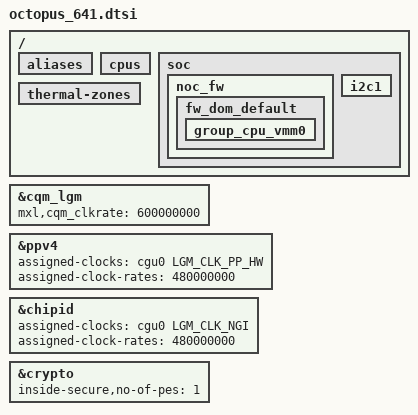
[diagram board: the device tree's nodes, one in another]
// SPDX-License-Identifier: GPL-2.0
/*
 * Copyright (C) 2022 MaxLinear, Inc.
 */

#include "octopus_851.dtsi"

/{
	aliases {
		/delete-property/ cpu2;
		/delete-property/ cpu3;
		/delete-property/ usb0;
		/delete-property/ pcie2;
		/delete-property/ pcie3;
		/delete-property/ pcie6;
		/delete-property/ pcie7;
		/delete-property/ cbphy1;
		/delete-property/ cbphy3;
	};

	cpus {
		/delete-node/ cpu@8;
		/delete-node/ cpu@a;
	};

	soc {
		/delete-node/ usb@0;
		/delete-node/ pcie@d1000000; /* PCIe30 */
		/delete-node/ pcie@d1100000; /* PCIe31 */
		/delete-node/ pcie@c1000000; /* PCIe40 */
		/delete-node/ pcie@c1100000; /* PCIe41 */
		/delete-node/ combophy1;
		/delete-node/ combophy3;

		noc_fw {
			fw_dom_default {
				group_cpu_vmm0 {
					/delete-node/ rule_cpu_vmm0_18;
					/delete-node/ rule_cpu_vmm0_19;
					/delete-node/ rule_cpu_vmm0_36;
					/delete-node/ rule_cpu_vmm0_37;
					/delete-node/ rule_cpu_vmm0_40;
					/delete-node/ rule_cpu_vmm0_41;
					/delete-node/ rule_cpu_vmm0_58;
					/delete-node/ rule_cpu_vmm0_59;
				};
			};
		};

		i2c1 {
			/delete-node/ ptn5150_1;
		};
	};

	thermal-zones {
		/delete-node/ cpu2-thermal;
		/delete-node/ cpu3-thermal;
	};
};

&cqm_lgm {
	mxl,cqm_clkrate = <600000000>;
};

&ppv4 {
	assigned-clocks = <&cgu0 LGM_CLK_PP_HW>;
	assigned-clock-rates = <480000000>;
};

&chipid {
	assigned-clocks = <&cgu0 LGM_CLK_NGI>;
	assigned-clock-rates = <480000000>;
};

&crypto {
	inside-secure,no-of-pes = <1>;
};
